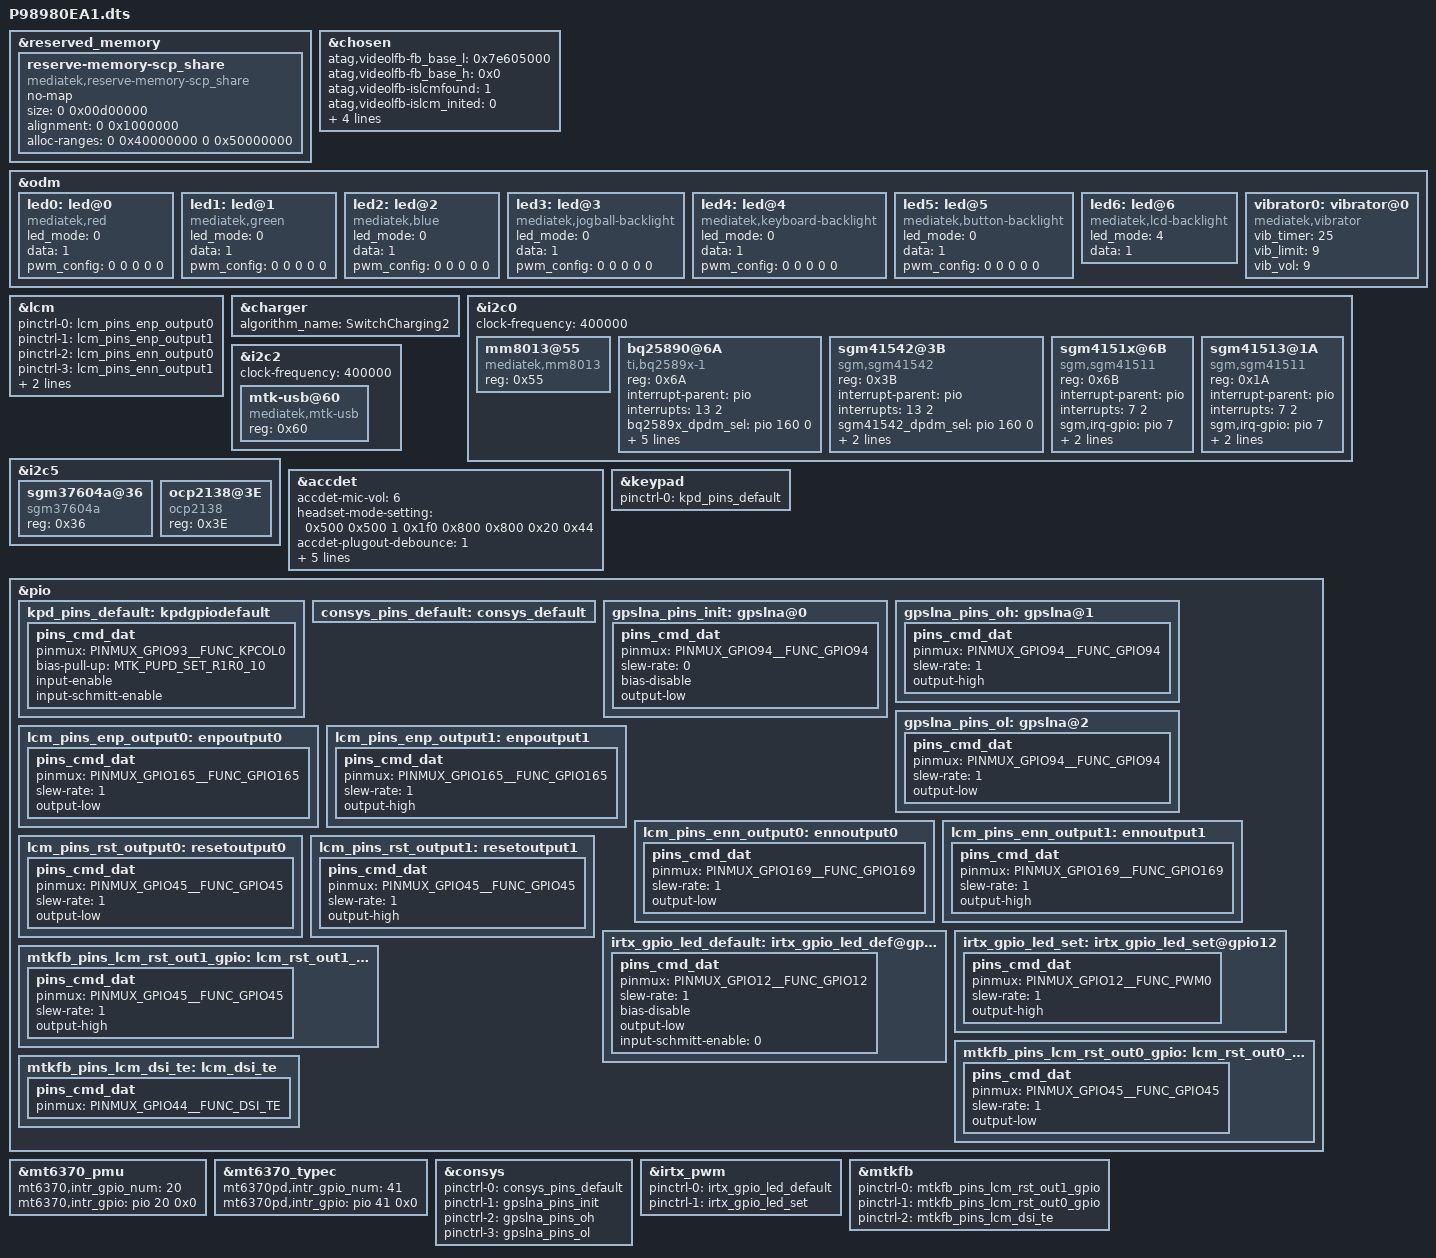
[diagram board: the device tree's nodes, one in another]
// SPDX-License-Identifier: GPL-2.0
/*
 * Copyright (c) 2019 MediaTek Inc.
 */

/dts-v1/;
/plugin/;
#include <dt-bindings/interrupt-controller/irq.h>
#include <dt-bindings/interrupt-controller/arm-gic.h>
#include <dt-bindings/pinctrl/mt6768-pinfunc.h>

&reserved_memory {
	reserve-memory-scp_share {
		compatible = "mediatek,reserve-memory-scp_share";
		no-map;
		size = <0 0x00d00000>;
		alignment = <0 0x1000000>;
		alloc-ranges = <0 0x40000000 0 0x50000000>;
	};
};

/* chosen */
&chosen {

	atag,videolfb-fb_base_l = <0x7e605000>;
	atag,videolfb-fb_base_h = <0x0>;
	atag,videolfb-islcmfound = <1>;
	atag,videolfb-islcm_inited = <0>;
	atag,videolfb-fps= <6000>;
	atag,videolfb-vramSize= <0x017e8000>;
	atag,videolfb-lcmname=
		"hx83112b_fhdp_dsi_cmd_auo_rt5081_drv";
};

&odm {
	led0:led@0 {
		compatible = "mediatek,red";
		led_mode = <0>;
		data = <1>;
		pwm_config = <0 0 0 0 0>;
	};
	led1:led@1 {
		compatible = "mediatek,green";
		led_mode = <0>;
		data = <1>;
		pwm_config = <0 0 0 0 0>;
	};
	led2:led@2 {
		compatible = "mediatek,blue";
		led_mode = <0>;
		data = <1>;
		pwm_config = <0 0 0 0 0>;
	};
	led3:led@3 {
		compatible = "mediatek,jogball-backlight";
		led_mode = <0>;
		data = <1>;
		pwm_config = <0 0 0 0 0>;
	};
	led4:led@4 {
		compatible = "mediatek,keyboard-backlight";
		led_mode = <0>;
		data = <1>;
		pwm_config = <0 0 0 0 0>;
	};
	led5:led@5 {
		compatible = "mediatek,button-backlight";
		led_mode = <0>;
		data = <1>;
		pwm_config = <0 0 0 0 0>;
	};
	led6:led@6 {
		compatible = "mediatek,lcd-backlight";
		led_mode = <4>;
		data = <1>;
		//pwm_config = <0 3 0 0 0>;
	};
	vibrator0:vibrator@0 {
		compatible = "mediatek,vibrator";
		vib_timer = <25>;
		vib_limit = <9>;
		vib_vol= <9>;
	};
};

&lcm {
	pinctrl-names = "state_enp_output0","state_enp_output1", "state_enn_output0",
               "state_enn_output1","state_reset_output0", "state_reset_output1";
	pinctrl-0 = <&lcm_pins_enp_output0>;
	pinctrl-1 = <&lcm_pins_enp_output1>;
	pinctrl-2 = <&lcm_pins_enn_output0>;
	pinctrl-3 = <&lcm_pins_enn_output1>;
	pinctrl-4 = <&lcm_pins_rst_output0>;
	pinctrl-5 = <&lcm_pins_rst_output1>;
	status = "okay";
};

&charger {
	algorithm_name = "SwitchCharging2";
};

&i2c0 {
	clock-frequency = <400000>;

	mm8013@55 {
		compatible = "mediatek,mm8013";
		reg = <0x55>;
		status = "okay";
	};

	bq25890@6A {
		compatible = "ti,bq2589x-1";
		reg = <0x6A>;
		status = "okay";

		#address-cells = <1>;
		#size-cells = <0>;
		interrupt-parent = <&pio>;
		interrupts = <13 2>;
		bq2589x_dpdm_sel = <&pio 160 0>;
		bq2589x_irq = <&pio 13 0>;
		bq2589x_en = <&pio 5 0>;
		ti,bq2589x,default-target-vol = <12000>;
		ti,bq2589x,charge-voltage = <4432>;
		ti,bq2589x,term-current = <256>;
	};

	sgm41542@3B {
		compatible = "sgm,sgm41542";
		reg = <0x3B>;
		status = "okay";

		#address-cells = <1>;
		#size-cells = <0>;
		interrupt-parent = <&pio>;
		interrupts = <13 2>;
		sgm41542_dpdm_sel = <&pio 160 0>;
		sgm41542_irq = <&pio 13 0>;
		default_pe_target_vbus = <12000>;
	};

	sgm4151x@6B {
		  compatible = "sgm,sgm41511";
		  reg = <0x6B>;
		  status = "okay";

		  interrupt-parent = <&pio>;
		  interrupts = <7 2>;
		  sgm,irq-gpio = <&pio 7 0>;
		  sgm,chg-en-gpio = <&pio 174 0>;
		  sgm,new-chg-en-gpio = <&pio 6 0>;
	};

	sgm41513@1A {
		  compatible = "sgm,sgm41511";
		  reg = <0x1A>;
		  status = "okay";

		  interrupt-parent = <&pio>;
		  interrupts = <7 2>;
		  sgm,irq-gpio = <&pio 7 0>;
		  sgm,chg-en-gpio = <&pio 174 0>;
		  sgm,new-chg-en-gpio = <&pio 6 0>;
	};
};

&i2c2 {
	clock-frequency = <400000>;

	mtk-usb@60 {
		compatible = "mediatek,mtk-usb";
		reg = <0x60>;
		status = "okay";
	};
};

&i2c5 {
        sgm37604a@36 {
                compatible = "sgm37604a";
                reg = <0x36>;
                status = "okay";
        };

        ocp2138@3E {
                compatible = "ocp2138";
                reg = <0x3E>;
                status = "okay";
        };
};

/* accdet start */
&accdet {
	/* accdet micbias voltage: 0x07,2.7v;0x05,2.5v;0x02,1.9v */
	accdet-mic-vol = <6>;
	headset-mode-setting = <0x500 0x500 1 0x1f0 0x800 0x800 0x20 0x44>;
	accdet-plugout-debounce = <1>;
	/*1:ACC mode, 2:low cost without in bias, 6:low cost with in bias*/
	accdet-mic-mode = <1>;
	/* eint_level_trigger: 8,LEVEL_LOW(DEF) ;4,LV_HIGH;others,LV_LOW */
	headset-eint-level-pol = <8>;
	/*0--MD_MAX--UP_MAX--DW_MAX*/
	headset-three-key-threshold = <0 80 220 400>;
	headset-three-key-threshold-CDD = <0 121 192 600>;
	/*0--MD_MAX--VOICE_MAX--UP_MAX--DW_MAX*/
	headset-four-key-threshold = <0 58 121 192 400>;
	status = "okay";
};
/* accdet end */

/* keypad start */
&keypad {
	pinctrl-names = "default";
	pinctrl-0 = <&kpd_pins_default>;
};

&pio {
	kpd_pins_default: kpdgpiodefault {
		pins_cmd_dat {
			pinmux = <PINMUX_GPIO93__FUNC_KPCOL0>;
			bias-pull-up = <MTK_PUPD_SET_R1R0_10>;
			input-enable;
			input-schmitt-enable;
		};
	};
};
/* keypad end */

&mt6370_pmu {
	mt6370,intr_gpio_num = <20>; /* direct defined GPIO num */
	mt6370,intr_gpio = <&pio 20 0x0>;
};
&mt6370_typec {
	mt6370pd,intr_gpio_num = <41>; /* direct defined GPIO num */
	mt6370pd,intr_gpio = <&pio 41 0x0>;
};

/* CONSYS GPIO standardization */
&pio {
	consys_pins_default: consys_default {
	};
	gpslna_pins_init: gpslna@0 {
		pins_cmd_dat {
			pinmux = <PINMUX_GPIO94__FUNC_GPIO94>;
			slew-rate = <0>;
			bias-disable;
			output-low;
		};
	};
	gpslna_pins_oh: gpslna@1 {
		pins_cmd_dat {
			pinmux = <PINMUX_GPIO94__FUNC_GPIO94>;
			slew-rate = <1>;
			output-high;
		};
	};
	gpslna_pins_ol: gpslna@2 {
		pins_cmd_dat {
			pinmux = <PINMUX_GPIO94__FUNC_GPIO94>;
			slew-rate = <1>;
			output-low;
		};
	};
        lcm_pins_enp_output0: enpoutput0 {
               pins_cmd_dat {
                       pinmux = <PINMUX_GPIO165__FUNC_GPIO165>;
                       slew-rate = <1>;
                       output-low;
               };
       };
       lcm_pins_enp_output1: enpoutput1 {
               pins_cmd_dat {
                       pinmux = <PINMUX_GPIO165__FUNC_GPIO165>;
                       slew-rate = <1>;
                       output-high;
               };
       };
       lcm_pins_enn_output0: ennoutput0 {
               pins_cmd_dat {
                       pinmux = <PINMUX_GPIO169__FUNC_GPIO169>;
                       slew-rate = <1>;
                       output-low;
               };
       };
       lcm_pins_enn_output1: ennoutput1 {
               pins_cmd_dat {
                       pinmux = <PINMUX_GPIO169__FUNC_GPIO169>;
                       slew-rate = <1>;
                       output-high;
               };
       };
       lcm_pins_rst_output0: resetoutput0 {
               pins_cmd_dat {
                       pinmux = <PINMUX_GPIO45__FUNC_GPIO45>;
                       slew-rate = <1>;
                       output-low;
               };
       };
       lcm_pins_rst_output1: resetoutput1 {
               pins_cmd_dat {
                       pinmux = <PINMUX_GPIO45__FUNC_GPIO45>;
                       slew-rate = <1>;
                       output-high;
               };
       };
};
&consys {
	pinctrl-names = "default", "gps_lna_state_init",
		"gps_lna_state_oh", "gps_lna_state_ol";
	pinctrl-0 = <&consys_pins_default>;
	pinctrl-1 = <&gpslna_pins_init>;
	pinctrl-2 = <&gpslna_pins_oh>;
	pinctrl-3 = <&gpslna_pins_ol>;
	status = "okay";
};
/* CONSYS end */

/* IRTX GPIO Start */
&irtx_pwm {
	pinctrl-names = "irtx_gpio_led_default", "irtx_gpio_led_set";
	pinctrl-0 = <&irtx_gpio_led_default>;
	pinctrl-1 = <&irtx_gpio_led_set>;
	status = "okay";
};
&pio {
	/* IRTX GPIO Settings -Start */
	/* default: GPIO0, output, high */
	irtx_gpio_led_default:irtx_gpio_led_def@gpio12 {
		pins_cmd_dat {
			pinmux = <PINMUX_GPIO12__FUNC_GPIO12>;
			slew-rate = <1>;
			bias-disable;
			output-low;
			input-schmitt-enable = <0>;
		};
	};

	irtx_gpio_led_set:irtx_gpio_led_set@gpio12 {
		pins_cmd_dat {
			pinmux = <PINMUX_GPIO12__FUNC_PWM0>;
			slew-rate = <1>;
			output-high;
		};
	};
}; /* IRTX GPIO Settings -End */

/* DISPSYS GPIO standardization */
&pio {
	mtkfb_pins_lcm_rst_out1_gpio: lcm_rst_out1_gpio {
		pins_cmd_dat {
			pinmux = <PINMUX_GPIO45__FUNC_GPIO45>;
			slew-rate = <1>;
			output-high;
		};
	};

	mtkfb_pins_lcm_rst_out0_gpio: lcm_rst_out0_gpio {
		pins_cmd_dat {
			pinmux = <PINMUX_GPIO45__FUNC_GPIO45>;
			slew-rate = <1>;
			output-low;
		};
	};

	mtkfb_pins_lcm_dsi_te: lcm_dsi_te {
		pins_cmd_dat {
			pinmux = <PINMUX_GPIO44__FUNC_DSI_TE>;
		};
	};
};

&mtkfb {
	pinctrl-names =
		"lcm_rst_out1_gpio", "lcm_rst_out0_gpio",
		"mode_te_te";
	pinctrl-0 = <&mtkfb_pins_lcm_rst_out1_gpio>;
	pinctrl-1 = <&mtkfb_pins_lcm_rst_out0_gpio>;
	pinctrl-2 = <&mtkfb_pins_lcm_dsi_te>;
	status = "okay";
};

/* DISPSYS GPIO standardization end*/

#include <P98980EA1/cust.dtsi>
#include "mediatek/cust_mt6768_camera.dtsi"
#include "mediatek/cust_mt6768_touch_1200x2000.dtsi"
/*End of this file, DO NOT ADD ANYTHING HERE*/
#include "mediatek/cust_foursemi.dtsi"
